# ATSAMD20E15 register map
Vendor: Atmel Corporation; Series: SAMD20; File version: D
CPU: CM0+ r0p1, little endian, no MPU, no FPU, VTOR, 2 interrupt priority bits
Registers are 8-bit, read-write, reset 0x0 unless marked. A register's access mark holds for its fields unless they carry their own. Offsets are from the block's base; [hi:lo] are bit positions; {n}, {i} and the like mark numbered series; 'fields as' and 'values as' point back to an identical list.

## SYSCTRL — System Control
Base 0x40000800
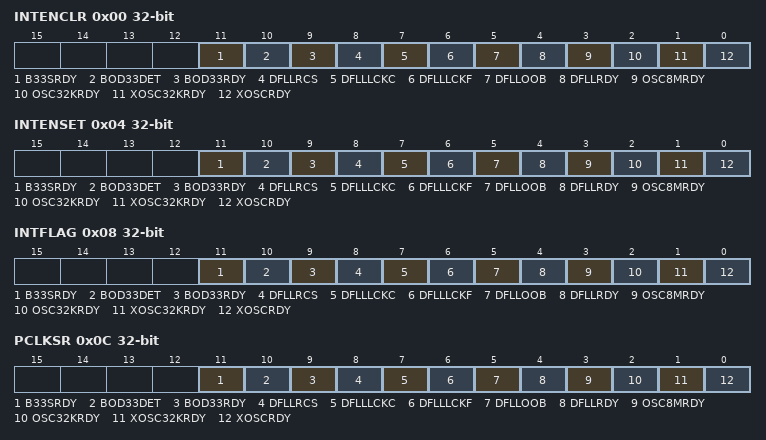
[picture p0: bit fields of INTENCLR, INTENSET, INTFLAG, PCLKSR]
0x00 INTENCLR 32-bit — Interrupt Enable Clear
  [11] B33SRDY — BOD33 Synchronization Ready
  [10] BOD33DET — BOD33 Detection
  [9] BOD33RDY — BOD33 Ready
  [8] DFLLRCS — DFLL Reference Clock Stopped
  [7] DFLLLCKC — DFLL Lock Coarse
  [6] DFLLLCKF — DFLL Lock Fine
  [5] DFLLOOB — DFLL Out Of Bounds
  [4] DFLLRDY — DFLL Ready
  [3] OSC8MRDY — OSC8M Ready
  [2] OSC32KRDY — OSC32K Ready
  [1] XOSC32KRDY — XOSC32K Ready
  [0] XOSCRDY — XOSC Ready
0x04 INTENSET 32-bit — Interrupt Enable Set
  fields as INTENCLR
0x08 INTFLAG 32-bit — Interrupt Flag Status and Clear
  fields as INTENCLR
0x0C PCLKSR 32-bit ro — Power and Clocks Status
  fields as INTENCLR
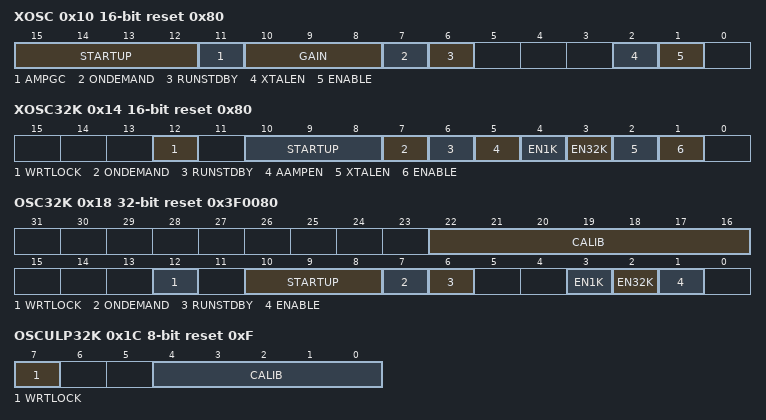
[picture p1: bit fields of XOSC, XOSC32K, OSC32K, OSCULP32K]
0x10 XOSC 16-bit reset 0x80 — XOSC Control
  [15:12] STARTUP — Start-Up Time
  [11] AMPGC — Automatic Amplitude Gain Control
  [10:8] GAIN — Gain Value
  [7] ONDEMAND — Enable on Demand
  [6] RUNSTDBY — Run during Standby
  [2] XTALEN — Crystal Oscillator Enable
  [1] ENABLE
0x14 XOSC32K 16-bit reset 0x80 — XOSC32K Control
  [12] WRTLOCK — Write Lock
  [10:8] STARTUP — Start-Up Time
  [7] ONDEMAND — Enable on Demand
  [6] RUNSTDBY — Run during Standby
  [5] AAMPEN — Automatic Amplitude Control Enable
  [4] EN1K — 1kHz Output Enable
  [3] EN32K — 32kHz Output Enable
  [2] XTALEN — Crystal Oscillator Enable
  [1] ENABLE
0x18 OSC32K 32-bit reset 0x3F0080 — OSC32K Control
  [22:16] CALIB — Calibration Value
  [12] WRTLOCK — Write Lock
  [10:8] STARTUP — Start-Up Time
  [7] ONDEMAND — Enable on Demand
  [6] RUNSTDBY — Run during Standby
  [3] EN1K — 1kHz Output Enable
  [2] EN32K — 32kHz Output Enable
  [1] ENABLE
0x1C OSCULP32K reset 0xF — OSCULP32K Control
  [7] WRTLOCK — Write Lock
  [4:0] CALIB — Calibration Value
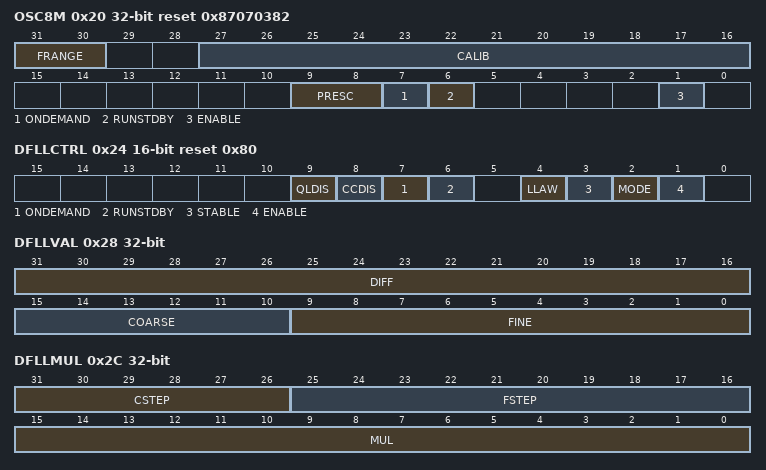
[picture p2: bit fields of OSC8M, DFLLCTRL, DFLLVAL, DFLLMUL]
0x20 OSC8M 32-bit reset 0x87070382 — OSC8M Control A
  [31:30] FRANGE — Frequency Range
  [27:16] CALIB — Calibration Value
  [9:8] PRESC — Prescaler Select
  [7] ONDEMAND — Enable on Demand
  [6] RUNSTDBY — Run during Standby
  [1] ENABLE
0x24 DFLLCTRL 16-bit reset 0x80 — DFLL Config
  [9] QLDIS — Quick Lock Disable
  [8] CCDIS — Chill Cycle Disable
  [7] ONDEMAND — Enable on Demand
  [6] RUNSTDBY — Run during Standby
  [4] LLAW — Lose Lock After Wake
  [3] STABLE — Stable Frequency
  [2] MODE — Mode Selection
  [1] ENABLE
0x28 DFLLVAL 32-bit — DFLL Calibration Value
  [31:16] DIFF ro — Multiplication Ratio Difference
  [15:10] COARSE — Coarse Calibration Value
  [9:0] FINE — Fine Calibration Value
0x2C DFLLMUL 32-bit — DFLL Multiplier
  [31:26] CSTEP — Maximum Coarse Step Size
  [25:16] FSTEP — Maximum Fine Step Size
  [15:0] MUL — Multiplication Value
0x30 DFLLSYNC — DFLL Synchronization
  [7] READREQ wo — Read Request Synchronization
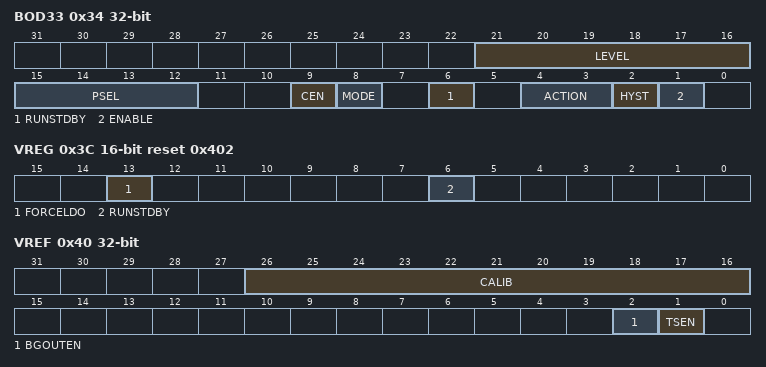
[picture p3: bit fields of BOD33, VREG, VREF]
0x34 BOD33 32-bit — 3.3V Brown-Out Detector (BOD33) Control
  [21:16] LEVEL — Threshold Level
  [15:12] PSEL — Prescaler Select
  [9] CEN — Clock Enable
  [8] MODE — Operation Modes
  [6] RUNSTDBY — Run during Standby
  [4:3] ACTION — Action when Threshold Crossed
  [2] HYST — Hysteresis Enable
  [1] ENABLE
0x3C VREG 16-bit reset 0x402 — VREG Control
  [13] FORCELDO — Force LDO Voltage Regulator
  [6] RUNSTDBY — Run during Standby
0x40 VREF 32-bit — VREF Control A
  [26:16] CALIB — Voltage Reference Calibration Value
  [2] BGOUTEN — Bandgap Output Enable
  [1] TSEN — Temperature Sensor Output Enable

## TC0 — Basic Timer Counter 0
Base 0x42002000
Same registers: TC1 0x42002400, TC2 0x42002800, TC3 0x42002C00, TC4 0x42003000, TC5 0x42003400
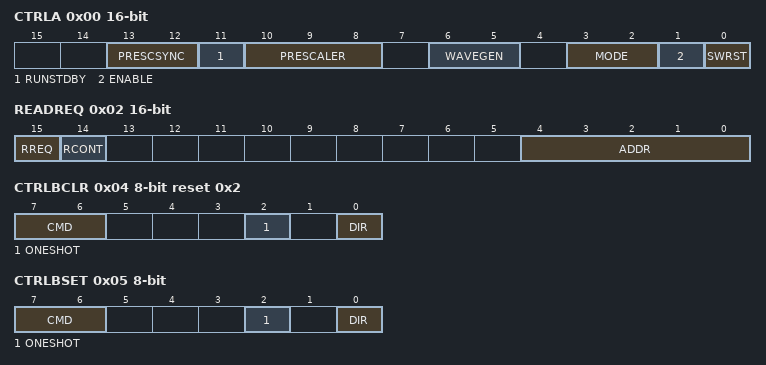
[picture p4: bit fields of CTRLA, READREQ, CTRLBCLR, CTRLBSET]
0x00 CTRLA 16-bit — Control A
  [13:12] PRESCSYNC — Prescaler and Counter Synchronization
    0=GCLK (Reload or reset Counter on next GCLK); 1=PRESC (Reload or reset Counter on next prescaler clock); 2=RESYNC (Reload or reset Counter on next GCLK. Reset prescaler counter)
  [11] RUNSTDBY — Run in Standby
  [10:8] PRESCALER
    0=DIV1 (GCLK_TC); 1=DIV2 (GCLK_TC/2); 2=DIV4 (GCLK_TC/4); 3=DIV8 (GCLK_TC/8); 4=DIV16 (GCLK_TC/16); 5=DIV64 (GCLK_TC/64); 6=DIV256 (GCLK_TC/256); 7=DIV1024 (GCLK_TC/1024)
  [6:5] WAVEGEN — Waveform Generation Operation
    0=NFRQ; 1=MFRQ; 2=NPWM; 3=MPWM
  [3:2] MODE — TC Mode
    0=COUNT16 (Counter in 16-bit mode); 1=COUNT8 (Counter in 8-bit mode); 2=COUNT32 (Counter in 32-bit mode)
  [1] ENABLE
  [0] SWRST wo — Software Reset
0x02 READREQ 16-bit — Read Request
  [15] RREQ — Read Request
  [14] RCONT — Read Continuously
  [4:0] ADDR — Address
0x04 CTRLBCLR reset 0x2 — Control B Clear
  [7:6] CMD — Command
    0=NONE (No action); 1=RETRIGGER (Force start, restart or retrigger); 2=STOP (Force stop)
  [2] ONESHOT
  [0] DIR — Counter Direction
0x05 CTRLBSET — Control B Set
  fields as CTRLBCLR
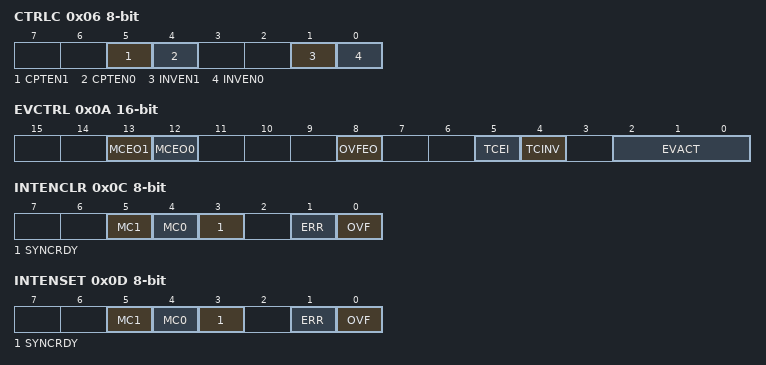
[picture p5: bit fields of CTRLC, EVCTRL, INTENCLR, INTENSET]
0x06 CTRLC — Control C
  [5] CPTEN1 — Capture Channel 1 Enable
  [4] CPTEN0 — Capture Channel 0 Enable
  [1] INVEN1 — Output Waveform 1 Invert Enable
  [0] INVEN0 — Output Waveform 0 Invert Enable
0x08 DBGCTRL — Debug Control
  [0] DBGRUN — Debug Run Mode
0x0A EVCTRL 16-bit — Event Control
  [13] MCEO1 — Match or Capture Channel 1 Event Output Enable
  [12] MCEO0 — Match or Capture Channel 0 Event Output Enable
  [8] OVFEO — Overflow/Underflow Event Output Enable
  [5] TCEI — TC Event Input
  [4] TCINV — TC Inverted Event Input
  [2:0] EVACT — Event Action
    0=OFF (Event action disabled); 1=RETRIGGER (Start, restart or retrigger TC on event); 2=COUNT (Count on event); 3=START (Start TC on event); 5=PPW (Period captured into CC0 Pulse Width in CC1); 6=PWP (Period captured into CC1 Pulse Width on CC0)
0x0C INTENCLR — Interrupt Enable Clear
  [5] MC1 — Match or Capture Channel 1 Interrupt Enable
  [4] MC0 — Match or Capture Channel 0 Interrupt Enable
  [3] SYNCRDY — Synchronization Ready Interrupt Enable
  [1] ERR — Error Interrupt Enable
  [0] OVF — Overflow Interrupt Enable
0x0D INTENSET — Interrupt Enable Set
  fields as INTENCLR
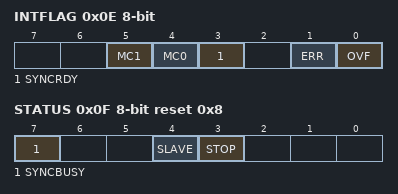
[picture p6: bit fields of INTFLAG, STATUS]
0x0E INTFLAG — Interrupt Flag Status and Clear
  [5] MC1 — Match or Capture Channel 1
  [4] MC0 — Match or Capture Channel 0
  [3] SYNCRDY — Synchronization Ready
  [1] ERR — Error
  [0] OVF — Overflow
0x0F STATUS ro reset 0x8
  [7] SYNCBUSY — Synchronization Busy
  [4] SLAVE
  [3] STOP
0x10 COUNT 16-bit — COUNT16 Counter Value
  [15:0] COUNT — Counter Value
{0x18+2i} CC{i} (i=0..1) 16-bit — COUNT16 Compare/Capture
  [15:0] CC — Compare/Capture Value

## WDT — Watchdog Timer
Base 0x40001000
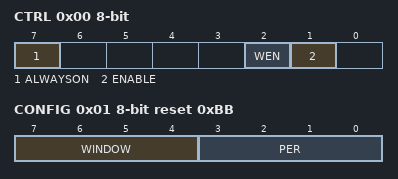
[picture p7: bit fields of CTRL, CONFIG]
0x00 CTRL — Control
  [7] ALWAYSON
  [2] WEN — Watchdog Timer Window Mode Enable
  [1] ENABLE
0x01 CONFIG reset 0xBB — Configuration
  [7:4] WINDOW — Window Mode Time-Out Period
    0=8 clock cycles; 1=16 clock cycles; 2=32 clock cycles; 3=64 clock cycles; 4=128 clock cycles; 5=256 clock cycles; 6=512 clock cycles; 7=1K (1024 clock cycles); 8=2K (2048 clock cycles); 9=4K (4096 clock cycles); 10=8K (8192 clock cycles); 11=16K (16384 clock cycles)
  [3:0] PER — Time-Out Period
    values as WINDOW
0x02 EWCTRL reset 0xB — Early Warning Interrupt Control
  [3:0] EWOFFSET — Early Warning Interrupt Time Offset
    values as CONFIG.WINDOW
0x04 INTENCLR — Interrupt Enable Clear
  [0] EW — Early Warning Interrupt Enable
0x05 INTENSET — Interrupt Enable Set
  [0] EW — Early Warning Interrupt Enable
0x06 INTFLAG — Interrupt Flag Status and Clear
  [0] EW — Early Warning
0x07 STATUS ro
  [7] SYNCBUSY — Synchronization Busy
0x08 CLEAR wo
  [7:0] CLEAR — Watchdog Clear
    165=KEY (Clear Key)
